# STM32F101xx register map
File version: 1.1
CPU: 
Registers are 32-bit, read-write, reset 0x0 unless marked. A register's access mark holds for its fields unless they carry their own. Offsets are from the block's base; lines under a group give offsets from that group; [hi:lo] are bit positions; {n}, {i} and the like mark numbered series; 'fields as' and 'values as' point back to an identical list; <NAME> marks a mode.

## Memory map
0x40000000 TIM2 size 0x400 — General purpose timer
0x40000400 TIM3 size 0x400 — General purpose timer
0x40000800 TIM4 size 0x400 — General purpose timer
0x40000C00 TIM5 size 0x400 — General purpose timer
0x40001000 TIM6 size 0x400 — Basic timer
0x40001400 TIM7 size 0x400 — Basic timer
0x40001800 TIM12 size 0x400 — General purpose timer
0x40001C00 TIM13 size 0x400 — General purpose timer
0x40002000 TIM14 size 0x400 — General purpose timer
0x40002800 RTC size 0x400 — Real time clock
0x40002C00 WWDG size 0x400 — Window watchdog
0x40003000 IWDG size 0x400 — Independent watchdog
0x40003800 SPI2 size 0x400 — Serial peripheral interface
0x40003C00 SPI3 size 0x400 — Serial peripheral interface
0x40004400 USART2 size 0x400 — Universal synchronous asynchronous receiver transmitter
0x40004800 USART3 size 0x400 — Universal synchronous asynchronous receiver transmitter
0x40004C00 UART4 size 0x400 — Universal asynchronous receiver transmitter
0x40005000 UART5 size 0x400 — Universal asynchronous receiver transmitter
0x40005400 I2C1 size 0x400 — Inter integrated circuit
0x40005800 I2C2 size 0x400 — Inter integrated circuit
0x40006C04 BKP size 0x400 — Backup registers
0x40007000 PWR size 0x400 — Power control
0x40007400 DAC size 0x400 — Digital to analog converter
0x40010000 AFIO size 0x400 — Alternate function I/O
0x40010400 EXTI size 0x400
0x40010800 GPIOA size 0x400 — General purpose I/O
0x40010C00 GPIOB size 0x400 — General purpose I/O
0x40011000 GPIOC size 0x400 — General purpose I/O
0x40011400 GPIOD size 0x400 — General purpose I/O
0x40011800 GPIOE size 0x400 — General purpose I/O
0x40011C00 GPIOF size 0x400 — General purpose I/O
0x40012000 GPIOG size 0x400 — General purpose I/O
0x40012400 ADC1 size 0x400 — Analog to digital converter
0x40013000 SPI1 size 0x400 — Serial peripheral interface
0x40013800 USART1 size 0x400 — Universal synchronous asynchronous receiver transmitter
0x40014C00 TIM9 size 0x400 — General purpose timer
0x40015000 TIM10 size 0x400 — General purpose timer
0x40015400 TIM11 size 0x400 — General purpose timer
0x40020000 DMA1 size 0x400 — DMA controller
0x40020400 DMA2 size 0x400 — DMA controller
0x40021000 RCC size 0x400 — Reset and clock control
0x40022000 FLASH size 0x400
0x40023000 CRC size 0x400 — CRC calculation unit
0xA0000000 FSMC size 0x1000 — Flexible static memory controller
0xE000E000 NVIC size 0x1001 — Nested Vectored Interrupt Controller
0xE0042000 DBG size 0x400 — Debug support

## Interrupts
0 WWDG (TIM2)
1 PVD (PWR)
2 TAMPER_STAMP (EXTI)
3 RTC_WKUP (RTC)
4 FLASH (BKP)
5 RCC
6 EXTI0 (EXTI)
7 EXTI1 (EXTI)
8 EXTI2 (EXTI)
9 EXTI3 (EXTI)
10 EXTI4 (EXTI)
11 DMA1_Channel1 (DMA1)
12 DMA1_Channel2 (DMA1)
13 DMA1_Channel3 (DMA1)
14 DMA1_Channel4 (DMA1)
15 DMA1_Channel5 (DMA1)
16 DMA1_Channel6 (DMA1)
17 DMA1_Channel7 (DMA1)
18 ADC_IRQ (ADC1)
21 DAC (UART4)
22 COMP_CA (EXTI)
23 EXTI9_5 (EXTI)
25 TIM9 (TIM12)
26 TIM10 (TIM11)
27 TIM11 (TIM13)
28 TIM2 (TIM3)
29 TIM3 (TIM4)
30 TIM4 (TIM5)
31 I2C1_EV (I2C2)
32 I2C1_ER (I2C2)
33 I2C2_EV (SPI1)
34 I2C2_ER (SPI1)
35 SPI1 (SPI2)
36 SPI2 (SPI3)
37 USART1 (USART2)
38 USART2 (USART3)
39 USART3 (DAC)
40 EXTI15_10 (EXTI)
41 RTC_Alarm (RTC)
43 TIM6 (TIM7)
44 TIM7 (I2C1)
46 TIM5 (TIM9)
47 SPI3 (USART1)
50 DMA2_CH1 (DMA2)
51 DMA2_CH2 (DMA2)
52 DMA2_CH3 (DMA2)
53 DMA2_CH4 (DMA2)
54 DMA2_CH5 (DMA2)

## FSMC — Flexible static memory controller
Base 0xA0000000
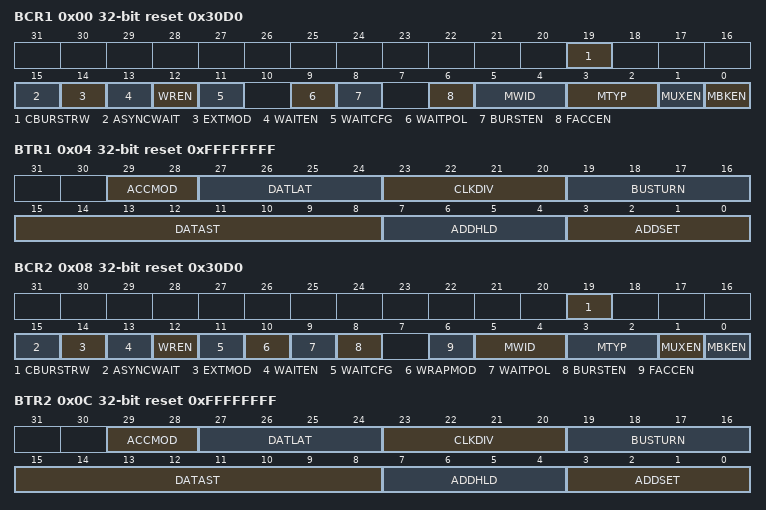
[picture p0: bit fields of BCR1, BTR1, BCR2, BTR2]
0x00 BCR1 reset 0x30D0 — SRAM/NOR-Flash chip-select control register 1
  [19] CBURSTRW, [15] ASYNCWAIT, [14] EXTMOD, [13] WAITEN, [12] WREN, [11] WAITCFG, [9] WAITPOL, [8] BURSTEN, [6] FACCEN, [5:4] MWID, [3:2] MTYP, [1] MUXEN, [0] MBKEN
0x04 BTR1 reset 0xFFFFFFFF — SRAM/NOR-Flash chip-select timing register 1
  [29:28] ACCMOD, [27:24] DATLAT, [23:20] CLKDIV, [19:16] BUSTURN, [15:8] DATAST, [7:4] ADDHLD, [3:0] ADDSET
0x08 BCR2 reset 0x30D0 — SRAM/NOR-Flash chip-select control register 2
  [19] CBURSTRW, [15] ASYNCWAIT, [14] EXTMOD, [13] WAITEN, [12] WREN, [11] WAITCFG, [10] WRAPMOD, [9] WAITPOL, [8] BURSTEN, [6] FACCEN, [5:4] MWID, [3:2] MTYP, [1] MUXEN, [0] MBKEN
0x0C BTR2 reset 0xFFFFFFFF — SRAM/NOR-Flash chip-select timing register 2
  fields as BTR1
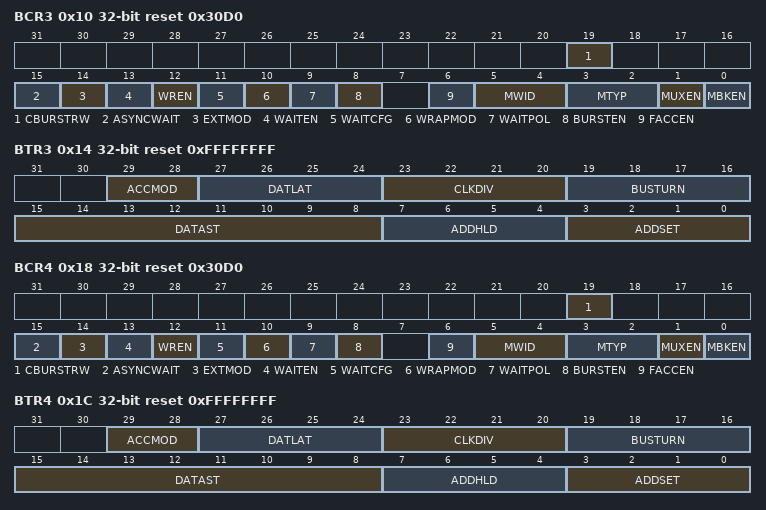
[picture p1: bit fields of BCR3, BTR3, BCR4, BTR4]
0x10 BCR3 reset 0x30D0 — SRAM/NOR-Flash chip-select control register 3
  fields as BCR2
0x14 BTR3 reset 0xFFFFFFFF — SRAM/NOR-Flash chip-select timing register 3
  fields as BTR1
0x18 BCR4 reset 0x30D0 — SRAM/NOR-Flash chip-select control register 4
  fields as BCR2
0x1C BTR4 reset 0xFFFFFFFF — SRAM/NOR-Flash chip-select timing register 4
  fields as BTR1
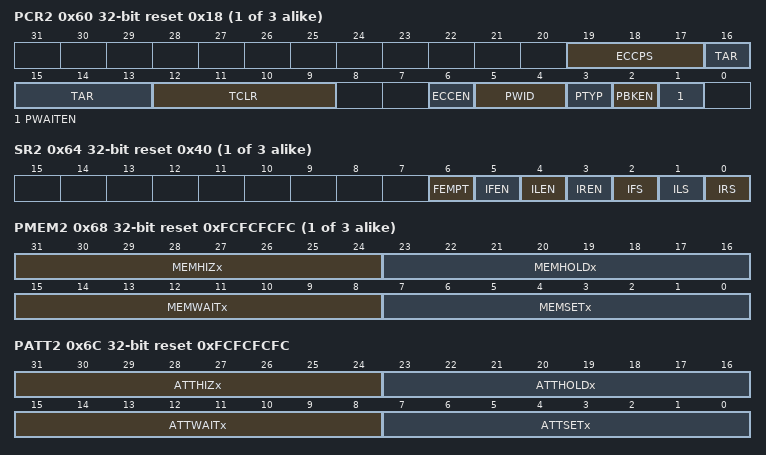
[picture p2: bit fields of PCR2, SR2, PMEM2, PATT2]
{0x20+0x20*i} PCR{i} reset 0x18 (i=2..4) — PC Card/NAND Flash control register {i}
  [19:17] ECCPS, [16:13] TAR, [12:9] TCLR, [6] ECCEN, [5:4] PWID, [3] PTYP, [2] PBKEN, [1] PWAITEN
{0x24+0x20*i} SR{i} access per field reset 0x40 (i=2..4) — FIFO status and interrupt register {i}
  [6] FEMPT ro, [5] IFEN rw, [4] ILEN rw, [3] IREN rw, [2] IFS rw, [1] ILS rw, [0] IRS rw
{0x28+0x20*i} PMEM{i} reset 0xFCFCFCFC (i=2..4) — Common memory space timing register {i}
  [31:24] MEMHIZx, [23:16] MEMHOLDx, [15:8] MEMWAITx, [7:0] MEMSETx
0x6C PATT2 reset 0xFCFCFCFC — Attribute memory space timing register 2
  [31:24] ATTHIZx — Attribute memory x databus HiZ time
  [23:16] ATTHOLDx — Attribute memory x hold time
  [15:8] ATTWAITx — Attribute memory x wait time
  [7:0] ATTSETx — Attribute memory x setup time
0x74 ECCR2 ro — ECC result register 2
  [31:0] ECCx — ECC result
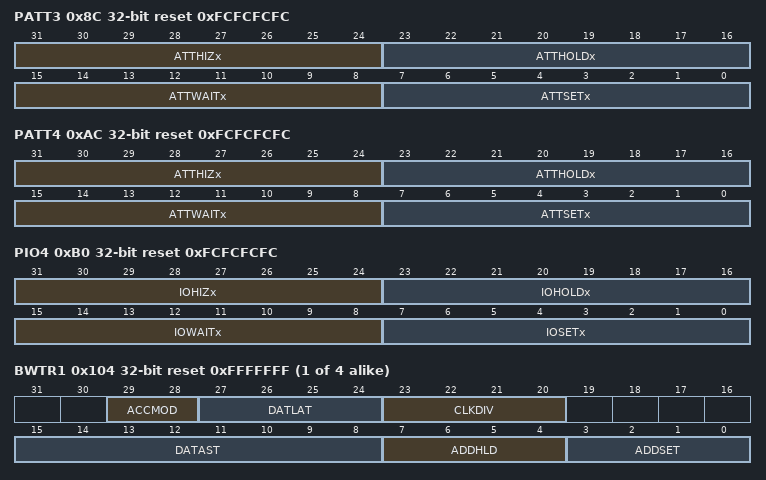
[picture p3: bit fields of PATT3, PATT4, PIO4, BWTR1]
0x8C PATT3 reset 0xFCFCFCFC — Attribute memory space timing register 3
  [31:24] ATTHIZx, [23:16] ATTHOLDx, [15:8] ATTWAITx, [7:0] ATTSETx
0x94 ECCR3 ro — ECC result register 3
  [31:0] ECCx
0xAC PATT4 reset 0xFCFCFCFC — Attribute memory space timing register 4
  [31:24] ATTHIZx, [23:16] ATTHOLDx, [15:8] ATTWAITx, [7:0] ATTSETx
0xB0 PIO4 reset 0xFCFCFCFC — I/O space timing register 4
  [31:24] IOHIZx, [23:16] IOHOLDx, [15:8] IOWAITx, [7:0] IOSETx
{0xFC+8i} BWTR{i} reset 0xFFFFFFF (i=1..4) — SRAM/NOR-Flash write timing registers {i}
  [29:28] ACCMOD, [27:24] DATLAT, [23:20] CLKDIV, [15:8] DATAST, [7:4] ADDHLD, [3:0] ADDSET
